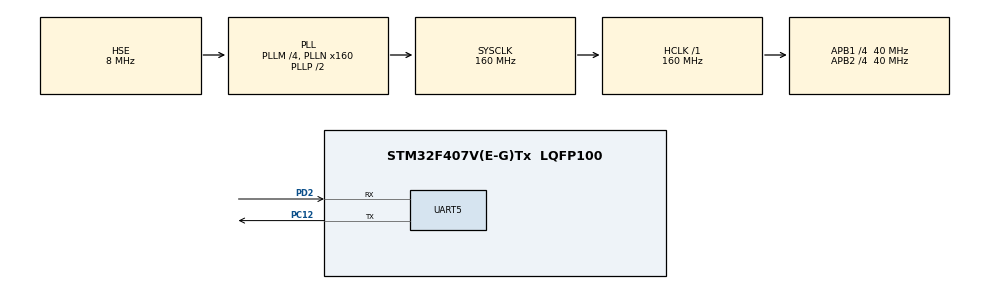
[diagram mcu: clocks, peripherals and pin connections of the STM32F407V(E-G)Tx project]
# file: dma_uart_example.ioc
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Dma.Request0=UART5_RX
Dma.Request1=UART5_TX
Dma.UART5_RX.0.Direction=DMA_PERIPH_TO_MEMORY
Dma.UART5_RX.0.FIFOMode=DMA_FIFOMODE_DISABLE
Dma.UART5_RX.0.Instance=DMA1_Stream0
Dma.UART5_RX.0.MemDataAlignment=DMA_MDATAALIGN_BYTE
Dma.UART5_RX.0.MemInc=DMA_MINC_ENABLE
Dma.UART5_RX.0.Mode=DMA_NORMAL
Dma.UART5_RX.0.PeriphDataAlignment=DMA_PDATAALIGN_BYTE
Dma.UART5_RX.0.PeriphInc=DMA_PINC_DISABLE
Dma.UART5_RX.0.Priority=DMA_PRIORITY_HIGH
Dma.UART5_TX.1.Direction=DMA_MEMORY_TO_PERIPH
Dma.UART5_TX.1.FIFOMode=DMA_FIFOMODE_DISABLE
Dma.UART5_TX.1.Instance=DMA1_Stream7
Dma.UART5_TX.1.MemDataAlignment=DMA_MDATAALIGN_BYTE
Dma.UART5_TX.1.MemInc=DMA_MINC_ENABLE
Dma.UART5_TX.1.Mode=DMA_NORMAL
Dma.UART5_TX.1.PeriphDataAlignment=DMA_PDATAALIGN_BYTE
Dma.UART5_TX.1.PeriphInc=DMA_PINC_DISABLE
Dma.UART5_TX.1.Priority=DMA_PRIORITY_MEDIUM
Mcu.Family=STM32F4
Mcu.Name=STM32F407V(E-G)Tx
Mcu.Package=LQFP100
NVIC.DMA1_Stream0_IRQn=true\:0\:0\:false\:false\:true\:false\:true
NVIC.DMA1_Stream7_IRQn=true\:0\:0\:false\:false\:true\:false\:true
NVIC.PriorityGroup=NVIC_PRIORITYGROUP_4
NVIC.UART5_IRQn=true\:0\:0\:false\:false\:true\:true\:true
PA13.Mode=Serial_Wire
PA13.Signal=SYS_JTMS-SWDIO
PA14.Mode=Serial_Wire
PA14.Signal=SYS_JTCK-SWCLK
PC12.Mode=Asynchronous
PC12.Signal=UART5_TX
PD2.Mode=Asynchronous
PD2.Signal=UART5_RX
PH0-OSC_IN.Mode=HSE-External-Oscillator
PH0-OSC_IN.Signal=RCC_OSC_IN
PH1-OSC_OUT.Mode=HSE-External-Oscillator
PH1-OSC_OUT.Signal=RCC_OSC_OUT
ProjectManager.HeapSize=0x200
ProjectManager.StackSize=0x400
ProjectManager.TargetToolchain=STM32CubeIDE
RCC.48MHZClocksFreq_Value=80000000
RCC.AHBFreq_Value=160000000
RCC.APB1CLKDivider=RCC_HCLK_DIV4
RCC.APB1Freq_Value=40000000
RCC.APB1TimFreq_Value=80000000
RCC.APB2CLKDivider=RCC_HCLK_DIV4
RCC.APB2Freq_Value=40000000
RCC.APB2TimFreq_Value=80000000
RCC.CortexFreq_Value=160000000
RCC.HCLKFreq_Value=160000000
RCC.HSE_VALUE=8000000
RCC.HSI_VALUE=16000000
RCC.LSE_VALUE=32768
RCC.PLLM=4
RCC.PLLN=160
RCC.PLLSourceVirtual=RCC_PLLSOURCE_HSE
RCC.SYSCLKFreq_VALUE=160000000
RCC.SYSCLKSource=RCC_SYSCLKSOURCE_PLLCLK
RCC.VCOOutputFreq_Value=320000000
UART5.VirtualMode=Asynchronous
board=custom

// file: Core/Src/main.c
/* USER CODE BEGIN Header */
/**
  ******************************************************************************
  * @file           : main.c
  * @brief          : Main program body
  ******************************************************************************
  * @attention
  *
  * <h2><center>&copy; Copyright (c) 2020 STMicroelectronics.
  * All rights reserved.</center></h2>
  *
  * This software component is licensed by ST under BSD 3-Clause license,
  * the "License"; You may not use this file except in compliance with the
  * License. You may obtain a copy of the License at:
  *                        opensource.org/licenses/BSD-3-Clause
  *
  ******************************************************************************
  */
/* USER CODE END Header */
#include "main.h"

UART_HandleTypeDef huart5;
DMA_HandleTypeDef hdma_uart5_rx;
DMA_HandleTypeDef hdma_uart5_tx;

/* USER CODE BEGIN PV */

#include <string.h>

uint8_t rxbuff[8];
uint8_t txbuff[8];
uint8_t txempty;
uint8_t rxfull;

void HAL_UART_RxCpltCallback(UART_HandleTypeDef *huart)
{
	if (huart == &huart5)
	{
		rxfull = 1;
	}
}

void HAL_UART_TxCpltCallback(UART_HandleTypeDef *huart)
{
	if (huart == &huart5)
	{
		txempty = 1;
	}
}

/* USER CODE END PV */

void SystemClock_Config(void);
static void MX_GPIO_Init(void);
static void MX_DMA_Init(void);
static void MX_UART5_Init(void);

int main(void)
{

  /* MCU Configuration--------------------------------------------------------*/

  /* Reset of all peripherals, Initializes the Flash interface and the Systick. */
  HAL_Init();

  /* Configure the system clock */
  SystemClock_Config();

  /* Initialize all configured peripherals */
  MX_GPIO_Init();
  MX_DMA_Init();
  MX_UART5_Init();
  /* USER CODE BEGIN 2 */

  rxfull = 0;
  txempty = 1;
  HAL_UART_Receive_DMA(&huart5, rxbuff, 8);

  /* USER CODE END 2 */

  /* Infinite loop */
  /* USER CODE BEGIN WHILE */
  while (1)
  {

	  if (rxfull == 1)
	  {
		  rxfull = 0;
		  memcpy(txbuff, rxbuff, 8);
		  for (uint8_t i=0; i < sizeof(txbuff)-1; ++i)
		  {
			  if (txbuff[i] < 255)
			  {
				  txbuff[i] += 1;
			  }
		  }
		  while(txempty == 0);
		  HAL_UART_Transmit_DMA(&huart5, txbuff, 8);
		  txempty = 0;

		  HAL_UART_Receive_DMA(&huart5, rxbuff, 8);
	  }

    /* USER CODE END WHILE */

  }
}

void SystemClock_Config(void)
{
  RCC_OscInitTypeDef RCC_OscInitStruct = {0};
  RCC_ClkInitTypeDef RCC_ClkInitStruct = {0};

  /** Configure the main internal regulator output voltage
  */
  __HAL_RCC_PWR_CLK_ENABLE();
  __HAL_PWR_VOLTAGESCALING_CONFIG(PWR_REGULATOR_VOLTAGE_SCALE1);
  /** Initializes the RCC Oscillators according to the specified parameters
  * in the RCC_OscInitTypeDef structure.
  */
  RCC_OscInitStruct.OscillatorType = RCC_OSCILLATORTYPE_HSE;
  RCC_OscInitStruct.HSEState = RCC_HSE_ON;
  RCC_OscInitStruct.PLL.PLLState = RCC_PLL_ON;
  RCC_OscInitStruct.PLL.PLLSource = RCC_PLLSOURCE_HSE;
  RCC_OscInitStruct.PLL.PLLM = 4;
  RCC_OscInitStruct.PLL.PLLN = 160;
  RCC_OscInitStruct.PLL.PLLP = RCC_PLLP_DIV2;
  RCC_OscInitStruct.PLL.PLLQ = 4;
  if (HAL_RCC_OscConfig(&RCC_OscInitStruct) != HAL_OK)
  {
    Error_Handler();
  }
  /** Initializes the CPU, AHB and APB buses clocks
  */
  RCC_ClkInitStruct.ClockType = RCC_CLOCKTYPE_HCLK|RCC_CLOCKTYPE_SYSCLK
                              |RCC_CLOCKTYPE_PCLK1|RCC_CLOCKTYPE_PCLK2;
  RCC_ClkInitStruct.SYSCLKSource = RCC_SYSCLKSOURCE_PLLCLK;
  RCC_ClkInitStruct.AHBCLKDivider = RCC_SYSCLK_DIV1;
  RCC_ClkInitStruct.APB1CLKDivider = RCC_HCLK_DIV4;
  RCC_ClkInitStruct.APB2CLKDivider = RCC_HCLK_DIV4;

  if (HAL_RCC_ClockConfig(&RCC_ClkInitStruct, FLASH_LATENCY_5) != HAL_OK)
  {
    Error_Handler();
  }
}

static void MX_UART5_Init(void)
{

  huart5.Instance = UART5;
  huart5.Init.BaudRate = 115200;
  huart5.Init.WordLength = UART_WORDLENGTH_8B;
  huart5.Init.StopBits = UART_STOPBITS_1;
  huart5.Init.Parity = UART_PARITY_NONE;
  huart5.Init.Mode = UART_MODE_TX_RX;
  huart5.Init.HwFlowCtl = UART_HWCONTROL_NONE;
  huart5.Init.OverSampling = UART_OVERSAMPLING_16;
  if (HAL_UART_Init(&huart5) != HAL_OK)
  {
    Error_Handler();
  }

}

static void MX_DMA_Init(void)
{

  /* DMA controller clock enable */
  __HAL_RCC_DMA1_CLK_ENABLE();

  /* DMA interrupt init */
  /* DMA1_Stream0_IRQn interrupt configuration */
  HAL_NVIC_SetPriority(DMA1_Stream0_IRQn, 0, 0);
  HAL_NVIC_EnableIRQ(DMA1_Stream0_IRQn);
  /* DMA1_Stream7_IRQn interrupt configuration */
  HAL_NVIC_SetPriority(DMA1_Stream7_IRQn, 0, 0);
  HAL_NVIC_EnableIRQ(DMA1_Stream7_IRQn);

}

static void MX_GPIO_Init(void)
{

  /* GPIO Ports Clock Enable */
  __HAL_RCC_GPIOH_CLK_ENABLE();
  __HAL_RCC_GPIOA_CLK_ENABLE();
  __HAL_RCC_GPIOC_CLK_ENABLE();
  __HAL_RCC_GPIOD_CLK_ENABLE();

}

void Error_Handler(void)
{
}

/************************ (C) COPYRIGHT STMicroelectronics *****END OF FILE****/
